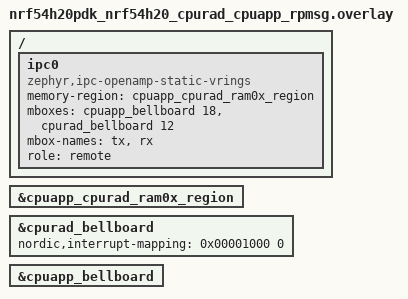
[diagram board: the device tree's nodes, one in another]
/*
 * Copyright (c) 2024 Nordic Semiconductor ASA
 * SPDX-License-Identifier: LicenseRef-Nordic-5-Clause
 */

 / {
	ipc0: ipc0 {
		compatible = "zephyr,ipc-openamp-static-vrings";
		memory-region = <&cpuapp_cpurad_ram0x_region>;
		mboxes = <&cpuapp_bellboard 18>,
			     <&cpurad_bellboard 12>;
		mbox-names = "tx", "rx";
		role = "remote";
		status = "okay";
	};
};

&cpuapp_cpurad_ram0x_region {
	status = "okay";
};

&cpurad_bellboard {
	status = "okay";
	nordic,interrupt-mapping = <0x00001000 0>;
};

&cpuapp_bellboard {
	status = "okay";
};
